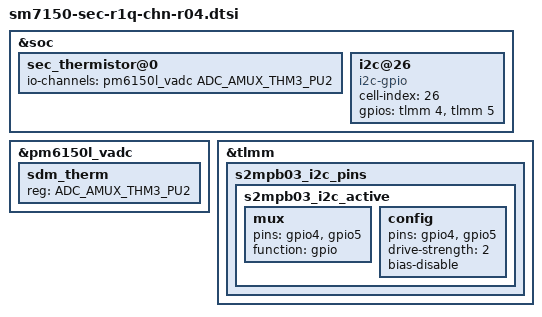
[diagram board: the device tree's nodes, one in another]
/* Copyright (c) 2018, The Linux Foundation. All rights reserved.
 *
 * This program is free software; you can redistribute it and/or modify
 * it under the terms of the GNU General Public License version 2 and
 * only version 2 as published by the Free Software Foundation.
 *
 * This program is distributed in the hope that it will be useful,
 * but WITHOUT ANY WARRANTY; without even the implied warranty of
 * MERCHANTABILITY or FITNESS FOR A PARTICULAR PURPOSE.  See the
 * GNU General Public License for more details.
 */

#include "sm7150-sec-r1q-chn-r03.dtsi"

&soc {
	sec_thermistor@0 {
		io-channels = <&pm6150l_vadc ADC_AMUX_THM3_PU2>;
	};

	/* S2MPB03 Camera PMIC */
	i2c@26 {
		cell-index = <26>;
		compatible = "i2c-gpio";
		gpios = <&tlmm 4 0 /* sda */
			&tlmm 5 0 /* scl */
		>;
	};
};

&pm6150l_vadc {
	sdm_therm {
		reg = <ADC_AMUX_THM3_PU2>;
	};
};

&tlmm {
	s2mpb03_i2c_pins {
		s2mpb03_i2c_active {
			mux {
				pins = "gpio4", "gpio5";
				function = "gpio";
			};
			config {
				pins = "gpio4", "gpio5";
				drive-strength = <2>;
				bias-disable;
			};
		};
	};
};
